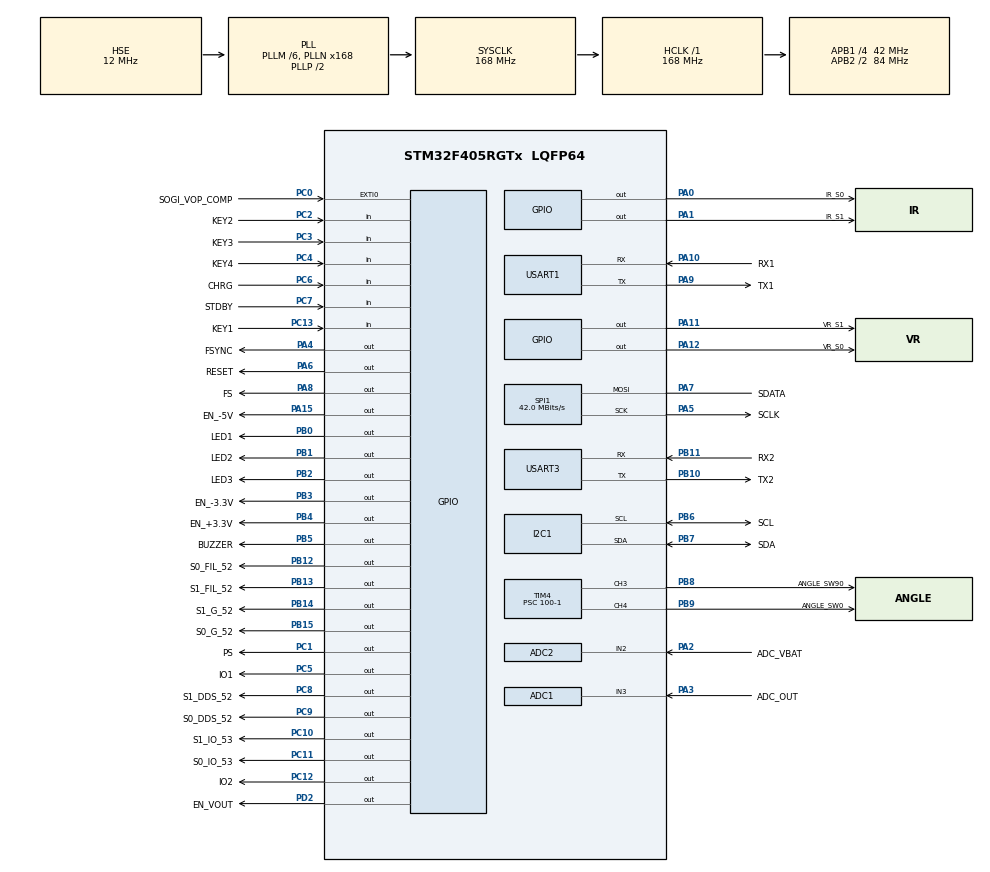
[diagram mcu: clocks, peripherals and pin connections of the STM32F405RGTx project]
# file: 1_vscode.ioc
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ADC1.Channel-0\#ChannelRegularConversion=ADC_CHANNEL_3
ADC1.NbrOfConversionFlag=1
ADC1.Rank-0\#ChannelRegularConversion=1
ADC1.SamplingTime-0\#ChannelRegularConversion=ADC_SAMPLETIME_480CYCLES
ADC1.master=1
ADC2.Channel-0\#ChannelRegularConversion=ADC_CHANNEL_2
ADC2.NbrOfConversionFlag=1
ADC2.Rank-0\#ChannelRegularConversion=1
ADC2.SamplingTime-0\#ChannelRegularConversion=ADC_SAMPLETIME_3CYCLES
Dma.ADC1.0.Direction=DMA_PERIPH_TO_MEMORY
Dma.ADC1.0.FIFOMode=DMA_FIFOMODE_DISABLE
Dma.ADC1.0.Instance=DMA2_Stream0
Dma.ADC1.0.MemDataAlignment=DMA_MDATAALIGN_HALFWORD
Dma.ADC1.0.MemInc=DMA_MINC_ENABLE
Dma.ADC1.0.Mode=DMA_CIRCULAR
Dma.ADC1.0.PeriphDataAlignment=DMA_PDATAALIGN_HALFWORD
Dma.ADC1.0.PeriphInc=DMA_PINC_DISABLE
Dma.ADC1.0.Priority=DMA_PRIORITY_HIGH
Dma.Request0=ADC1
FREERTOS.Mutexes01=Mutex_Result,Dynamic,NULL,Available
FREERTOS.Queues01=Queue_Cmd,16,uint8_t,0,Dynamic,NULL,NULL
FREERTOS.Tasks01=Task_Measure,40,512,StartMeasureTask,Default,NULL,Dynamic,NULL,NULL;Task_Display,24,512,StartDisplayTask,Default,NULL,Dynamic,NULL,NULL;Task_Key,8,256,StartKeyTask,Default,NULL,Dynamic,NULL,NULL
Mcu.Family=STM32F4
Mcu.Name=STM32F405RGTx
Mcu.Package=LQFP64
NVIC.ADC_IRQn=true\:5\:0\:false\:false\:true\:true\:true\:true\:true
NVIC.DMA2_Stream0_IRQn=true\:5\:0\:false\:false\:true\:true\:false\:true\:true
NVIC.EXTI0_IRQn=true\:5\:0\:false\:false\:true\:true\:true\:true\:true
NVIC.PriorityGroup=NVIC_PRIORITYGROUP_4
NVIC.TIM6_DAC_IRQn=true\:5\:0\:false\:false\:true\:true\:true\:true\:true
NVIC.TIM7_IRQn=true\:15\:0\:false\:false\:true\:false\:false\:true\:true
NVIC.TimeBase=TIM7_IRQn
NVIC.TimeBaseIP=TIM7
PA0-WKUP.GPIO_Label=IR_S0
PA0-WKUP.GPIO_Speed=GPIO_SPEED_FREQ_MEDIUM
PA0-WKUP.Signal=GPIO_Output
PA1.GPIO_Label=IR_S1
PA1.GPIO_Speed=GPIO_SPEED_FREQ_MEDIUM
PA1.Signal=GPIO_Output
PA10.GPIO_Label=RX1
PA10.Mode=Asynchronous
PA10.Signal=USART1_RX
PA11.GPIO_Label=VR_S1
PA11.GPIO_Speed=GPIO_SPEED_FREQ_MEDIUM
PA11.Signal=GPIO_Output
PA12.GPIO_Label=VR_S0
PA12.GPIO_Speed=GPIO_SPEED_FREQ_MEDIUM
PA12.Signal=GPIO_Output
PA13.Mode=Serial_Wire
PA13.Signal=SYS_JTMS-SWDIO
PA14.Mode=Serial_Wire
PA14.Signal=SYS_JTCK-SWCLK
PA15.GPIO_Label=EN_-5V
PA15.GPIO_Speed=GPIO_SPEED_FREQ_MEDIUM
PA15.Signal=GPIO_Output
PA2.GPIO_Label=ADC_VBAT
PA2.Signal=ADCx_IN2
PA3.GPIO_Label=ADC_OUT
PA3.Signal=ADCx_IN3
PA4.GPIO_Label=FSYNC
PA4.GPIO_Speed=GPIO_SPEED_FREQ_MEDIUM
PA4.Signal=GPIO_Output
PA5.GPIO_Label=SCLK
PA5.Mode=Simplex_Bidirectional_Master
PA5.Signal=SPI1_SCK
PA6.GPIO_Label=RESET
PA6.GPIO_Speed=GPIO_SPEED_FREQ_MEDIUM
PA6.Signal=GPIO_Output
PA7.GPIO_Label=SDATA
PA7.Mode=Simplex_Bidirectional_Master
PA7.Signal=SPI1_MOSI
PA8.GPIO_Label=FS
PA8.GPIO_Speed=GPIO_SPEED_FREQ_MEDIUM
PA8.Signal=GPIO_Output
PA9.GPIO_Label=TX1
PA9.Mode=Asynchronous
PA9.Signal=USART1_TX
PB0.GPIO_Label=LED1
PB0.GPIO_Speed=GPIO_SPEED_FREQ_MEDIUM
PB0.Signal=GPIO_Output
PB1.GPIO_Label=LED2
PB1.GPIO_Speed=GPIO_SPEED_FREQ_MEDIUM
PB1.Signal=GPIO_Output
PB10.GPIO_Label=TX2
PB10.Mode=Asynchronous
PB10.Signal=USART3_TX
PB11.GPIO_Label=RX2
PB11.Mode=Asynchronous
PB11.Signal=USART3_RX
PB12.GPIO_Label=S0_FIL_52
PB12.GPIO_Speed=GPIO_SPEED_FREQ_MEDIUM
PB12.Signal=GPIO_Output
PB13.GPIO_Label=S1_FIL_52
PB13.GPIO_Speed=GPIO_SPEED_FREQ_MEDIUM
PB13.Signal=GPIO_Output
PB14.GPIO_Label=S1_G_52
PB14.GPIO_Speed=GPIO_SPEED_FREQ_MEDIUM
PB14.Signal=GPIO_Output
PB15.GPIO_Label=S0_G_52
PB15.GPIO_Speed=GPIO_SPEED_FREQ_MEDIUM
PB15.Signal=GPIO_Output
PB2.GPIO_Label=LED3
PB2.GPIO_Speed=GPIO_SPEED_FREQ_MEDIUM
PB2.Signal=GPIO_Output
PB3.GPIO_Label=EN_-3.3V
PB3.GPIO_Speed=GPIO_SPEED_FREQ_MEDIUM
PB3.Signal=GPIO_Output
PB4.GPIO_Label=EN_+3.3V
PB4.GPIO_Speed=GPIO_SPEED_FREQ_MEDIUM
PB4.Signal=GPIO_Output
PB5.GPIO_Label=BUZZER
PB5.GPIO_Speed=GPIO_SPEED_FREQ_MEDIUM
PB5.Signal=GPIO_Output
PB6.GPIO_Label=SCL
PB6.Mode=I2C
PB6.Signal=I2C1_SCL
PB7.GPIO_Label=SDA
PB7.Mode=I2C
PB7.Signal=I2C1_SDA
PB8.GPIO_Label=ANGLE_SW90
PB8.Signal=S_TIM4_CH3
PB9.GPIO_Label=ANGLE_SW0
PB9.Signal=S_TIM4_CH4
PC0.GPIO_Label=SOGI_VOP_COMP
PC0.GPIO_ModeDefaultEXTI=GPIO_MODE_IT_RISING
PC0.Signal=GPXTI0
PC1.GPIO_Label=PS
PC1.Signal=GPIO_Output
PC10.GPIO_Label=S1_IO_53
PC10.GPIO_Speed=GPIO_SPEED_FREQ_MEDIUM
PC10.Signal=GPIO_Output
PC11.GPIO_Label=S0_IO_53
PC11.GPIO_Speed=GPIO_SPEED_FREQ_MEDIUM
PC11.Signal=GPIO_Output
PC12.GPIO_Label=IO2
PC12.GPIO_Speed=GPIO_SPEED_FREQ_MEDIUM
PC12.Signal=GPIO_Output
PC13-ANTI_TAMP.GPIO_Label=KEY1
PC13-ANTI_TAMP.GPIO_PuPd=GPIO_PULLUP
PC13-ANTI_TAMP.Signal=GPIO_Input
PC2.GPIO_Label=KEY2
PC2.GPIO_PuPd=GPIO_PULLUP
PC2.Signal=GPIO_Input
PC3.GPIO_Label=KEY3
PC3.GPIO_PuPd=GPIO_PULLUP
PC3.Signal=GPIO_Input
PC4.GPIO_Label=KEY4
PC4.GPIO_PuPd=GPIO_PULLUP
PC4.Signal=GPIO_Input
PC5.GPIO_Label=IO1
PC5.GPIO_Speed=GPIO_SPEED_FREQ_MEDIUM
PC5.Signal=GPIO_Output
PC6.GPIO_Label=CHRG
PC6.GPIO_PuPd=GPIO_PULLUP
PC6.Signal=GPIO_Input
PC7.GPIO_Label=STDBY
PC7.GPIO_PuPd=GPIO_PULLUP
PC7.Signal=GPIO_Input
PC8.GPIO_Label=S1_DDS_52
PC8.GPIO_Speed=GPIO_SPEED_FREQ_MEDIUM
PC8.Signal=GPIO_Output
PC9.GPIO_Label=S0_DDS_52
PC9.GPIO_Speed=GPIO_SPEED_FREQ_MEDIUM
PC9.Signal=GPIO_Output
PD2.GPIO_Label=EN_VOUT
PD2.Signal=GPIO_Output
PH0-OSC_IN.Mode=HSE-External-Oscillator
PH0-OSC_IN.Signal=RCC_OSC_IN
PH1-OSC_OUT.Mode=HSE-External-Oscillator
PH1-OSC_OUT.Signal=RCC_OSC_OUT
ProjectManager.HeapSize=0x200
ProjectManager.StackSize=0x400
ProjectManager.TargetToolchain=Makefile
RCC.48MHZClocksFreq_Value=84000000
RCC.AHBFreq_Value=168000000
RCC.APB1CLKDivider=RCC_HCLK_DIV4
RCC.APB1Freq_Value=42000000
RCC.APB1TimFreq_Value=84000000
RCC.APB2CLKDivider=RCC_HCLK_DIV2
RCC.APB2Freq_Value=84000000
RCC.APB2TimFreq_Value=168000000
RCC.CortexFreq_Value=168000000
RCC.HCLKFreq_Value=168000000
RCC.HSE_VALUE=12000000
RCC.HSI_VALUE=16000000
RCC.LSE_VALUE=32768
RCC.PLLM=6
RCC.PLLN=168
RCC.PLLSourceVirtual=RCC_PLLSOURCE_HSE
RCC.SYSCLKFreq_VALUE=168000000
RCC.SYSCLKSource=RCC_SYSCLKSOURCE_PLLCLK
RCC.VCOOutputFreq_Value=336000000
SH.ADCx_IN2.0=ADC1_IN2
SH.ADCx_IN2.1=ADC2_IN2,IN2
SH.ADCx_IN3.0=ADC1_IN3,IN3
SH.S_TIM4_CH3.0=TIM4_CH3,Output Compare3 CH3
SH.S_TIM4_CH4.0=TIM4_CH4,Output Compare4 CH4
SPI1.BaudRatePrescaler=SPI_BAUDRATEPRESCALER_2
SPI1.CalculateBaudRate=42.0 MBits/s
SPI1.Direction=SPI_DIRECTION_1LINE
SPI1.Mode=SPI_MODE_MASTER
SPI1.VirtualType=VM_MASTER
TIM4.Channel-Output\ Compare3\ CH3=TIM_CHANNEL_3
TIM4.Channel-Output\ Compare4\ CH4=TIM_CHANNEL_4
TIM4.OCMode_3=TIM_OCMODE_TOGGLE
TIM4.OCMode_4=TIM_OCMODE_TOGGLE
TIM4.OCPolarity_3=TIM_OCPOLARITY_LOW
TIM4.OCPolarity_4=TIM_OCPOLARITY_LOW
TIM4.Period=840 - 1
TIM4.Prescaler=100-1
TIM4.Pulse-Output\ Compare4\ CH4=420
TIM6.Period=1000-1
TIM6.Prescaler=168-1
USART1.VirtualMode=VM_ASYNC
USART3.VirtualMode=VM_ASYNC
VP_FREERTOS_VS_CMSIS_V2.Mode=CMSIS_V2
VP_SYS_VS_tim7.Mode=TIM7
VP_TIM4_VS_ClockSourceINT.Mode=Internal
VP_TIM6_VS_ClockSourceINT.Mode=Enable_Timer
board=custom

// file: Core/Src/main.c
/* USER CODE BEGIN Header */
/**
  ******************************************************************************
  * @file           : main.c
  * @brief          : Main program body
  ******************************************************************************
  * @attention
  *
  * Copyright (c) 2026 STMicroelectronics.
  * All rights reserved.
  *
  * This software is licensed under terms that can be found in the LICENSE file
  * in the root directory of this software component.
  * If no LICENSE file comes with this software, it is provided AS-IS.
  *
  ******************************************************************************
  */
/* USER CODE END Header */
#include "main.h"
#include "cmsis_os.h"
#include "adc.h"
#include "dma.h"
#include "i2c.h"
#include "spi.h"
#include "tim.h"
#include "usart.h"
#include "gpio.h"

void SystemClock_Config(void);
void MX_FREERTOS_Init(void);

int main(void)
{

  /* MCU Configuration--------------------------------------------------------*/

  /* Reset of all peripherals, Initializes the Flash interface and the Systick. */
  HAL_Init();

  /* Configure the system clock */
  SystemClock_Config();

  /* Initialize all configured peripherals */
  MX_GPIO_Init();
  MX_DMA_Init();
  MX_ADC1_Init();
  MX_TIM4_Init();
  MX_TIM6_Init();
  MX_I2C1_Init();
  MX_SPI1_Init();
  MX_USART1_UART_Init();
  MX_USART3_UART_Init();
  MX_ADC2_Init();

  /* Init scheduler */
  osKernelInitialize();  /* Call init function for freertos objects (in cmsis_os2.c) */
  MX_FREERTOS_Init();

  /* Start scheduler */
  osKernelStart();

  /* We should never get here as control is now taken by the scheduler */

  /* Infinite loop */
  while (1)
  {

  }
}

void SystemClock_Config(void)
{
  RCC_OscInitTypeDef RCC_OscInitStruct = {0};
  RCC_ClkInitTypeDef RCC_ClkInitStruct = {0};

  /** Configure the main internal regulator output voltage
  */
  __HAL_RCC_PWR_CLK_ENABLE();
  __HAL_PWR_VOLTAGESCALING_CONFIG(PWR_REGULATOR_VOLTAGE_SCALE1);

  /** Initializes the RCC Oscillators according to the specified parameters
  * in the RCC_OscInitTypeDef structure.
  */
  RCC_OscInitStruct.OscillatorType = RCC_OSCILLATORTYPE_HSE;
  RCC_OscInitStruct.HSEState = RCC_HSE_ON;
  RCC_OscInitStruct.PLL.PLLState = RCC_PLL_ON;
  RCC_OscInitStruct.PLL.PLLSource = RCC_PLLSOURCE_HSE;
  RCC_OscInitStruct.PLL.PLLM = 6;
  RCC_OscInitStruct.PLL.PLLN = 168;
  RCC_OscInitStruct.PLL.PLLP = RCC_PLLP_DIV2;
  RCC_OscInitStruct.PLL.PLLQ = 4;
  if (HAL_RCC_OscConfig(&RCC_OscInitStruct) != HAL_OK)
  {
    Error_Handler();
  }

  /** Initializes the CPU, AHB and APB buses clocks
  */
  RCC_ClkInitStruct.ClockType = RCC_CLOCKTYPE_HCLK|RCC_CLOCKTYPE_SYSCLK
                              |RCC_CLOCKTYPE_PCLK1|RCC_CLOCKTYPE_PCLK2;
  RCC_ClkInitStruct.SYSCLKSource = RCC_SYSCLKSOURCE_PLLCLK;
  RCC_ClkInitStruct.AHBCLKDivider = RCC_SYSCLK_DIV1;
  RCC_ClkInitStruct.APB1CLKDivider = RCC_HCLK_DIV4;
  RCC_ClkInitStruct.APB2CLKDivider = RCC_HCLK_DIV2;

  if (HAL_RCC_ClockConfig(&RCC_ClkInitStruct, FLASH_LATENCY_5) != HAL_OK)
  {
    Error_Handler();
  }
}

void HAL_TIM_PeriodElapsedCallback(TIM_HandleTypeDef *htim)
{
  if (htim->Instance == TIM7)
  {
    HAL_IncTick();
  }
}

void Error_Handler(void)
{
  __disable_irq();
  while (1)
  {
  }
}

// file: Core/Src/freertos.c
/* USER CODE BEGIN Header */
/**
  ******************************************************************************
  * File Name          : freertos.c
  * Description        : Code for freertos applications
  ******************************************************************************
  * @attention
  *
  * Copyright (c) 2026 STMicroelectronics.
  * All rights reserved.
  *
  * This software is licensed under terms that can be found in the LICENSE file
  * in the root directory of this software component.
  * If no LICENSE file comes with this software, it is provided AS-IS.
  *
  ******************************************************************************
  */
/* USER CODE END Header */

#include "FreeRTOS.h"
#include "task.h"
#include "main.h"
#include "cmsis_os.h"

/* USER CODE BEGIN Includes */
#include "app_display.h"
#include "app_key.h"
#include "app_measure.h"

/* USER CODE END Includes */

/* Definitions for Task_Measure */
osThreadId_t Task_MeasureHandle;
const osThreadAttr_t Task_Measure_attributes = {
  .name = "Task_Measure",
  .stack_size = 512 * 4,
  .priority = (osPriority_t) osPriorityHigh,
};
/* Definitions for Task_Display */
osThreadId_t Task_DisplayHandle;
const osThreadAttr_t Task_Display_attributes = {
  .name = "Task_Display",
  .stack_size = 512 * 4,
  .priority = (osPriority_t) osPriorityNormal,
};
/* Definitions for Task_Key */
osThreadId_t Task_KeyHandle;
const osThreadAttr_t Task_Key_attributes = {
  .name = "Task_Key",
  .stack_size = 256 * 4,
  .priority = (osPriority_t) osPriorityLow,
};
/* Definitions for Queue_Cmd */
osMessageQueueId_t Queue_CmdHandle;
const osMessageQueueAttr_t Queue_Cmd_attributes = {
  .name = "Queue_Cmd"
};
/* Definitions for Mutex_Result */
osMutexId_t Mutex_ResultHandle;
const osMutexAttr_t Mutex_Result_attributes = {
  .name = "Mutex_Result"
};

void StartMeasureTask(void *argument);
void StartDisplayTask(void *argument);
void StartKeyTask(void *argument);

void MX_FREERTOS_Init(void); /* (MISRA C 2004 rule 8.1) */

void MX_FREERTOS_Init(void) {
  /* Create the mutex(es) */
  /* creation of Mutex_Result */
  Mutex_ResultHandle = osMutexNew(&Mutex_Result_attributes);

  /* Create the queue(s) */
  /* creation of Queue_Cmd */
  Queue_CmdHandle = osMessageQueueNew (16, sizeof(uint8_t), &Queue_Cmd_attributes);

  /* Create the thread(s) */
  /* creation of Task_Measure */
  Task_MeasureHandle = osThreadNew(StartMeasureTask, NULL, &Task_Measure_attributes);

  /* creation of Task_Display */
  Task_DisplayHandle = osThreadNew(StartDisplayTask, NULL, &Task_Display_attributes);

  /* creation of Task_Key */
  Task_KeyHandle = osThreadNew(StartKeyTask, NULL, &Task_Key_attributes);

}

void StartMeasureTask(void *argument)
{
  /* USER CODE BEGIN StartMeasureTask */
  App_Measure_Init();
  /* Infinite loop */
  for(;;)
  {
    App_Measure_Run();
  }
  /* USER CODE END StartMeasureTask */
}

void StartDisplayTask(void *argument)
{
  /* USER CODE BEGIN StartDisplayTask */
  App_Display_Init();
  /* Infinite loop */
  for(;;)
  {
    App_Display_Run();
  }
  /* USER CODE END StartDisplayTask */
}

void StartKeyTask(void *argument)
{
  /* USER CODE BEGIN StartKeyTask */
  App_Key_Init();
  /* Infinite loop */
  for(;;)
  {
    App_Key_Run();
  }
  /* USER CODE END StartKeyTask */
}
